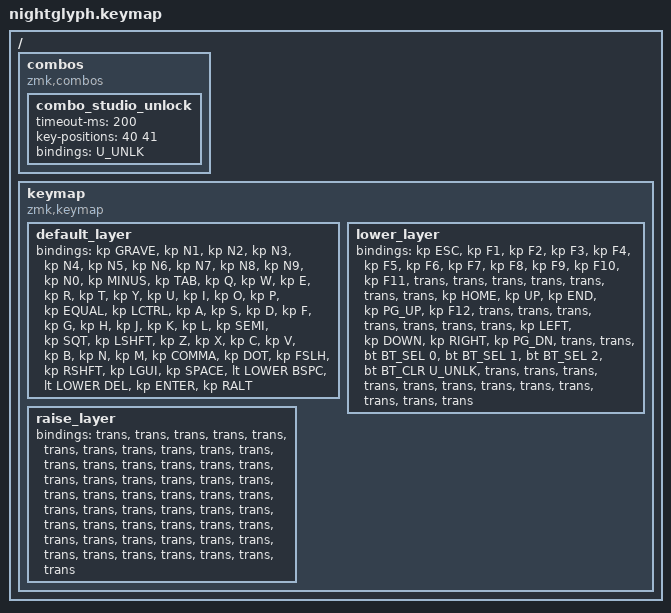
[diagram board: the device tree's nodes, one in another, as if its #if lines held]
/*
 * NightGlyph キーマップ（ZMK Studio対応・合体transform版）
 *
 * ┌───┬───┬───┬───┬───┬───┐   ┌───┬───┬───┬───┬───┬───┐
 * │ ` │ 1 │ 2 │ 3 │ 4 │ 5 │   │ 6 │ 7 │ 8 │ 9 │ 0 │ - │
 * ├───┼───┼───┼───┼───┼───┤   ├───┼───┼───┼───┼───┼───┤
 * │Tab│ Q │ W │ E │ R │ T │   │ Y │ U │ I │ O │ P │ = │
 * ├───┼───┼───┼───┼───┼───┤   ├───┼───┼───┼───┼───┼───┤
 * │Ctl│ A │ S │ D │ F │ G │   │ H │ J │ K │ L │ ; │ ' │
 * ├───┼───┼───┼───┼───┼───┤   ├───┼───┼───┼───┼───┼───┤
 * │Sft│ Z │ X │ C │ V │ B │   │ N │ M │ , │ . │ / │Sft│
 * └───┴───┴───┼───┼───┼───┘   └───┼───┼───┼───┴───┴───┘
 *             │GUI│Spc│BSP│   │DEL│Ent│RAl│
 *             └───┴───┴───┘   └───┴───┴───┘
 *
 * 合体transform(列0-11)なので bindings は「各行 左6→右6 の12個」順。
 */

#include <behaviors.dtsi>
#include <dt-bindings/zmk/keys.h>
#include <dt-bindings/zmk/bt.h>

#define DEFAULT 0
#define LOWER   1
#define RAISE   2

/* ZMK Studio 編集ロック解除キー。左(セントラル)だけ有効、右は&transで無害化 */
#if defined(CONFIG_ZMK_STUDIO)
#define U_UNLK &studio_unlock
#else
#define U_UNLK &trans
#endif

/ {
    /* V と B を同時押しで ZMK Studio のロック解除 */
    combos {
        compatible = "zmk,combos";
        combo_studio_unlock {
            timeout-ms = <200>;
            key-positions = <40 41>;
            bindings = <U_UNLK>;
        };
    };

    keymap {
        compatible = "zmk,keymap";

        default_layer {
            bindings = <
                &kp GRAVE  &kp N1     &kp N2     &kp N3     &kp N4     &kp N5       &kp N6     &kp N7     &kp N8     &kp N9     &kp N0     &kp MINUS
                &kp TAB    &kp Q      &kp W      &kp E      &kp R      &kp T        &kp Y      &kp U      &kp I      &kp O      &kp P      &kp EQUAL
                &kp LCTRL  &kp A      &kp S      &kp D      &kp F      &kp G        &kp H      &kp J      &kp K      &kp L      &kp SEMI   &kp SQT
                &kp LSHFT  &kp Z      &kp X      &kp C      &kp V      &kp B        &kp N      &kp M      &kp COMMA  &kp DOT    &kp FSLH   &kp RSHFT
                &kp LGUI   &kp SPACE  &lt LOWER BSPC                               &lt LOWER DEL  &kp ENTER  &kp RALT
            >;
        };

        lower_layer {
            bindings = <
                &kp ESC    &kp F1         &kp F2         &kp F3         &kp F4       &kp F5       &kp F6     &kp F7     &kp F8     &kp F9     &kp F10    &kp F11
                &trans     &trans         &trans         &trans         &trans       &trans       &trans     &kp HOME   &kp UP     &kp END    &kp PG_UP  &kp F12
                &trans     &trans         &trans         &trans         &trans       &trans       &trans     &kp LEFT   &kp DOWN   &kp RIGHT  &kp PG_DN  &trans
                &trans     &bt BT_SEL 0   &bt BT_SEL 1   &bt BT_SEL 2   &bt BT_CLR   U_UNLK       &trans     &trans     &trans     &trans     &trans     &trans
                &trans     &trans         &trans                                                  &trans     &trans     &trans
            >;
        };

        raise_layer {
            bindings = <
                &trans     &trans     &trans     &trans     &trans     &trans       &trans     &trans     &trans     &trans     &trans     &trans
                &trans     &trans     &trans     &trans     &trans     &trans       &trans     &trans     &trans     &trans     &trans     &trans
                &trans     &trans     &trans     &trans     &trans     &trans       &trans     &trans     &trans     &trans     &trans     &trans
                &trans     &trans     &trans     &trans     &trans     &trans       &trans     &trans     &trans     &trans     &trans     &trans
                &trans     &trans     &trans                                        &trans     &trans     &trans
            >;
        };
    };
};
